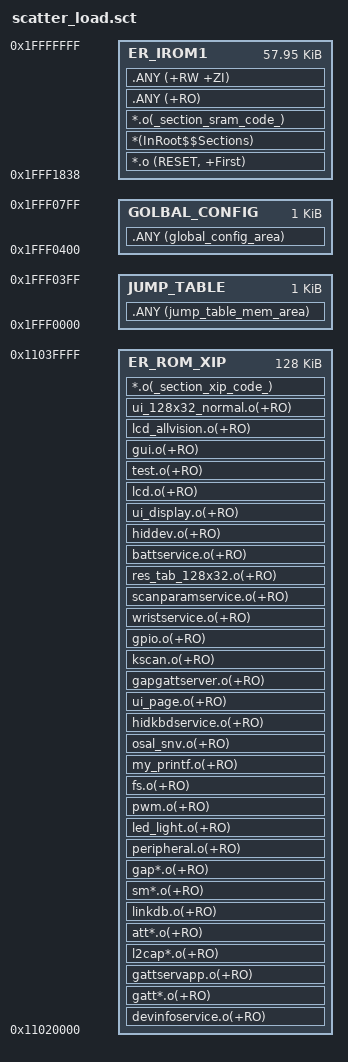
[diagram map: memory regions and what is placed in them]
; *************************************************************
; *** Scatter-Loading Description File generated by uVision ***
; *************************************************************

LR_IROM1 0x1fff1838 0x0E7C8 {  ; load region size_region
 ER_IROM1 0x1fff1838 0x0E7C8  {  ; load address = execution address
  *.o (RESET, +First)
  *(InRoot$$Sections)
  *.o(_section_sram_code_)
  .ANY (+RO)  
  .ANY (+RW +ZI)
 }
}
LR_ROM_JT_GC  0x1fff0000 0x00800 {
  JUMP_TABLE 0x1fff0000 0x00400  {
   .ANY (jump_table_mem_area) 
	
  }
  GOLBAL_CONFIG 0x1fff0400 0x00400  {
   .ANY (global_config_area) 
	
  }  
 } 
LR_ROM_XIP  0x11020000 0x020000 {
  ER_ROM_XIP 0x11020000 0x020000  {  ; load address = execution address
   devinfoservice.o(+RO)
   gatt*.o(+RO)
   gattservapp.o(+RO)
   l2cap*.o(+RO)
   att*.o(+RO)
   linkdb.o(+RO)
   sm*.o(+RO)
   gap*.o(+RO)
   peripheral.o(+RO)
   led_light.o(+RO)
   pwm.o(+RO)
   ;ota_app_service.O(+RO)
   ;key.o(+RO)
   ;cliface.o(+RO)
   fs.o(+RO)
   ;log.o(+RO)
   my_printf.o(+RO)
   osal_snv.o(+RO)
   hidkbdservice.o(+RO)
   ui_page.o(+RO)
   ;peripheral.o(+RO)
   gapgattserver.o(+RO)
   kscan.o(+RO)
   gpio.o(+RO)
   wristservice.o(+RO)
   ;hidkbdservice.o(+RO)
   scanparamservice.o(+RO)
   res_tab_128x32.o(+RO)
   battservice.o(+RO)
   hiddev.o(+RO)
   ui_display.o(+RO)
   lcd.o(+RO)
   test.o(+RO)
   gui.o(+RO)
   lcd_allvision.o(+RO)
   ui_128x32_normal.o(+RO)
   *.o(_section_xip_code_)
  }
 }  



